# ioam3358 register map
Registers are 32-bit, access not given, no defined reset value unless marked. A register's access mark holds for its fields unless they carry their own. Addresses are absolute; registers are grouped by the start of their names; [hi:lo] are bit positions; {n}, {i} and the like mark numbered series; 'fields as' and 'values as' point back to an identical list.

## LCDC
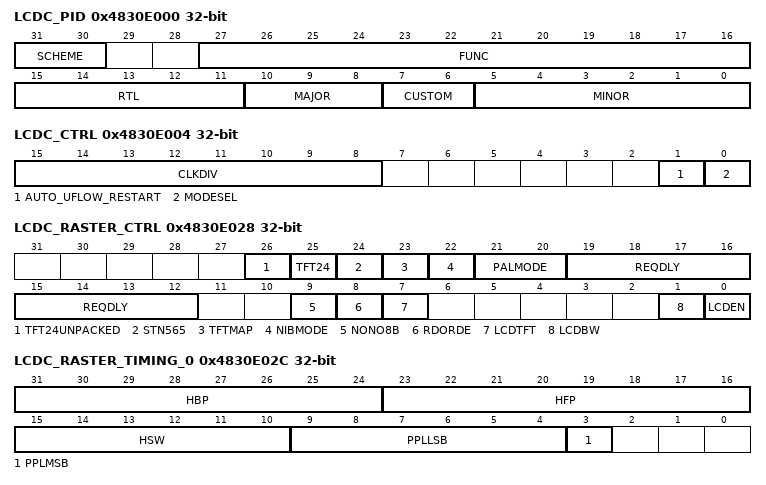
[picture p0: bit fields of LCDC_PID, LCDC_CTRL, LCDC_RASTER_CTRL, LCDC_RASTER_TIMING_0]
0x4830E000 LCDC_PID
  [31:30] SCHEME, [27:16] FUNC, [15:11] RTL, [10:8] MAJOR, [7:6] CUSTOM, [5:0] MINOR
0x4830E004 LCDC_CTRL
  [15:8] CLKDIV, [1] AUTO_UFLOW_RESTART, [0] MODESEL
0x4830E028 LCDC_RASTER_CTRL
  [26] TFT24UNPACKED, [25] TFT24, [24] STN565, [23] TFTMAP, [22] NIBMODE, [21:20] PALMODE, [19:12] REQDLY, [9] NONO8B, [8] RDORDE, [7] LCDTFT, [1] LCDBW, [0] LCDEN
0x4830E02C LCDC_RASTER_TIMING_0
  [31:24] HBP, [23:16] HFP, [15:10] HSW, [9:4] PPLLSB, [3] PPLMSB
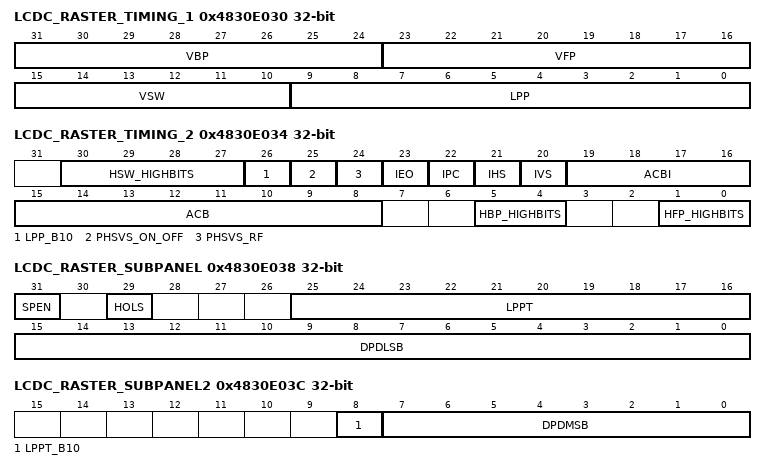
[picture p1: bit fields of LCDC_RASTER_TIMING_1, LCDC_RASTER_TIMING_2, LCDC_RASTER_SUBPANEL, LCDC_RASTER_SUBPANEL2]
0x4830E030 LCDC_RASTER_TIMING_1
  [31:24] VBP, [23:16] VFP, [15:10] VSW, [9:0] LPP
0x4830E034 LCDC_RASTER_TIMING_2
  [30:27] HSW_HIGHBITS, [26] LPP_B10, [25] PHSVS_ON_OFF, [24] PHSVS_RF, [23] IEO, [22] IPC, [21] IHS, [20] IVS, [19:16] ACBI, [15:8] ACB, [5:4] HBP_HIGHBITS, [1:0] HFP_HIGHBITS
0x4830E038 LCDC_RASTER_SUBPANEL
  [31] SPEN, [29] HOLS, [25:16] LPPT, [15:0] DPDLSB
0x4830E03C LCDC_RASTER_SUBPANEL2
  [8] LPPT_B10, [7:0] DPDMSB
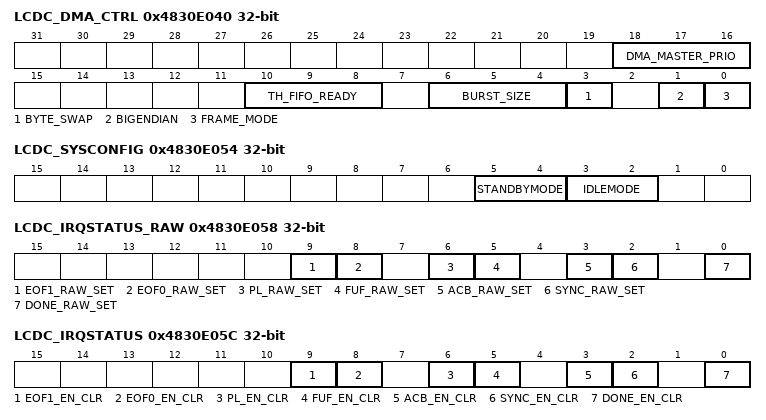
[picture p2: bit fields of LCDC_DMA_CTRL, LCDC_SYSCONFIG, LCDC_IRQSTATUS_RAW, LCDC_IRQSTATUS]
0x4830E040 LCDC_DMA_CTRL
  [18:16] DMA_MASTER_PRIO, [10:8] TH_FIFO_READY, [6:4] BURST_SIZE, [3] BYTE_SWAP, [1] BIGENDIAN, [0] FRAME_MODE
0x4830E044 LCDC_DMA_FB0_BASE
0x4830E048 LCDC_DMA_FB0_CEILING
0x4830E04C LCDC_DMA_FB1_BASE
0x4830E050 LCDC_DMA_FB1_CEILING
0x4830E054 LCDC_SYSCONFIG
  [5:4] STANDBYMODE, [3:2] IDLEMODE
0x4830E058 LCDC_IRQSTATUS_RAW
  [9] EOF1_RAW_SET, [8] EOF0_RAW_SET, [6] PL_RAW_SET, [5] FUF_RAW_SET, [3] ACB_RAW_SET, [2] SYNC_RAW_SET, [0] DONE_RAW_SET
0x4830E05C LCDC_IRQSTATUS
  [9] EOF1_EN_CLR, [8] EOF0_EN_CLR, [6] PL_EN_CLR, [5] FUF_EN_CLR, [3] ACB_EN_CLR, [2] SYNC_EN_CLR, [0] DONE_EN_CLR
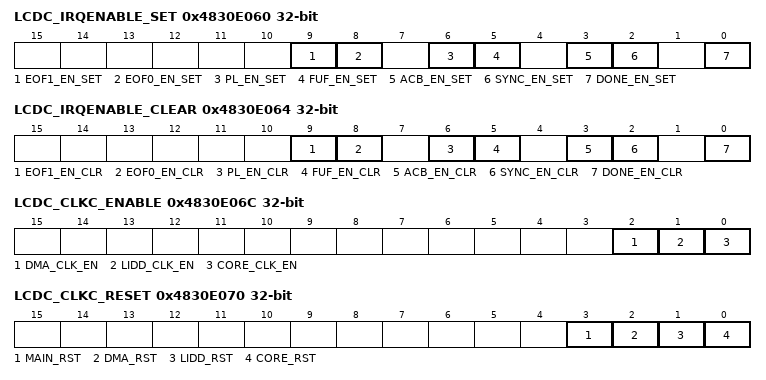
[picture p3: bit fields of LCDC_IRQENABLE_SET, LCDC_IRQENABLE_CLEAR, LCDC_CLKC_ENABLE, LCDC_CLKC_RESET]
0x4830E060 LCDC_IRQENABLE_SET
  [9] EOF1_EN_SET, [8] EOF0_EN_SET, [6] PL_EN_SET, [5] FUF_EN_SET, [3] ACB_EN_SET, [2] SYNC_EN_SET, [0] DONE_EN_SET
0x4830E064 LCDC_IRQENABLE_CLEAR
  fields as LCDC_IRQSTATUS
0x4830E068 LCDC_IRQEOI_VECTOR
0x4830E06C LCDC_CLKC_ENABLE
  [2] DMA_CLK_EN, [1] LIDD_CLK_EN, [0] CORE_CLK_EN
0x4830E070 LCDC_CLKC_RESET
  [3] MAIN_RST, [2] DMA_RST, [1] LIDD_RST, [0] CORE_RST

## LIDD
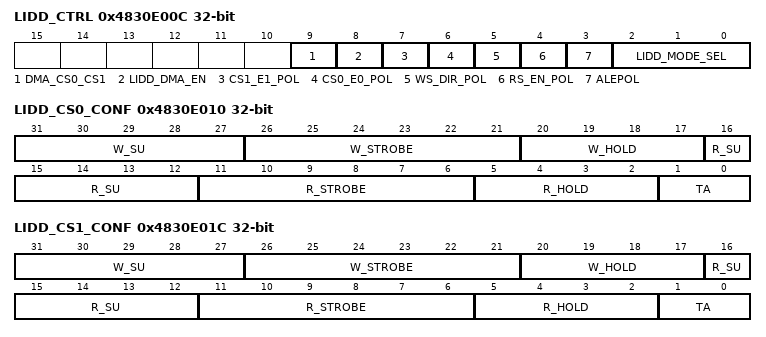
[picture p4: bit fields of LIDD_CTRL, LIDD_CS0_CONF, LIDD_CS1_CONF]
0x4830E00C LIDD_CTRL
  [9] DMA_CS0_CS1, [8] LIDD_DMA_EN, [7] CS1_E1_POL, [6] CS0_E0_POL, [5] WS_DIR_POL, [4] RS_EN_POL, [3] ALEPOL, [2:0] LIDD_MODE_SEL
0x4830E010 LIDD_CS0_CONF
  [31:27] W_SU, [26:21] W_STROBE, [20:17] W_HOLD, [16:12] R_SU, [11:6] R_STROBE, [5:2] R_HOLD, [1:0] TA
0x4830E014 LIDD_CS0_ADDR
  [15:0] ADR_INDX
0x4830E018 LIDD_CS0_DATA
  [15:0] DATA
0x4830E01C LIDD_CS1_CONF
  fields as LIDD_CS0_CONF
0x4830E020 LIDD_CS1_ADDR
  [15:0] ADR_INDX
0x4830E024 LIDD_CS1_DATA
  [15:0] DATA

## MDIO
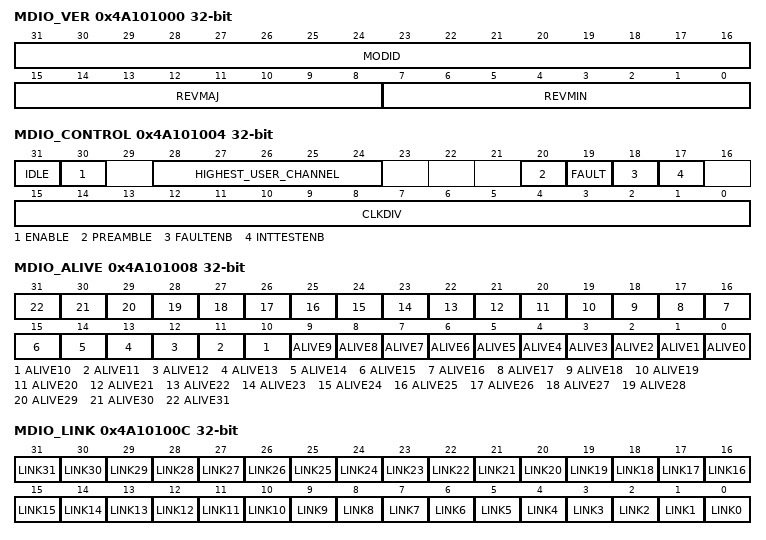
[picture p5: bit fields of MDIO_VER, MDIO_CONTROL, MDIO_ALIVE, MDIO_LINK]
0x4A101000 MDIO_VER
  [31:16] MODID, [15:8] REVMAJ, [7:0] REVMIN
0x4A101004 MDIO_CONTROL
  [31] IDLE, [30] ENABLE, [28:24] HIGHEST_USER_CHANNEL, [20] PREAMBLE, [19] FAULT, [18] FAULTENB, [17] INTTESTENB, [15:0] CLKDIV
0x4A101008 MDIO_ALIVE
  [n] ALIVE{n} (n=0..31)
0x4A10100C MDIO_LINK
  [n] LINK{n} (n=0..31)
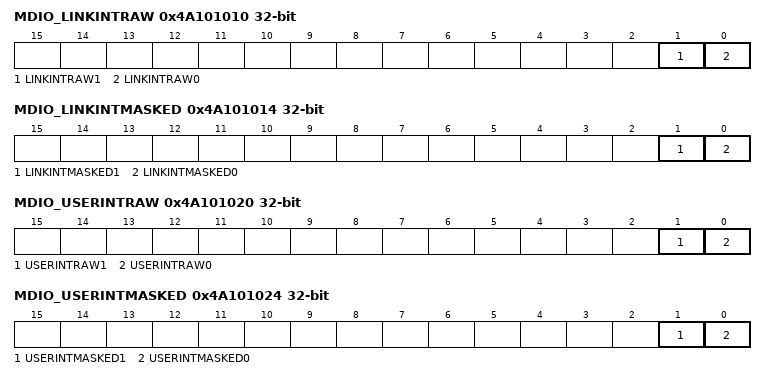
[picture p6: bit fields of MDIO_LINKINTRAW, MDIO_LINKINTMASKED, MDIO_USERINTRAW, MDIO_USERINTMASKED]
0x4A101010 MDIO_LINKINTRAW
  [1] LINKINTRAW1, [0] LINKINTRAW0
0x4A101014 MDIO_LINKINTMASKED
  [1] LINKINTMASKED1, [0] LINKINTMASKED0
0x4A101020 MDIO_USERINTRAW
  [1] USERINTRAW1, [0] USERINTRAW0
0x4A101024 MDIO_USERINTMASKED
  [1] USERINTMASKED1, [0] USERINTMASKED0
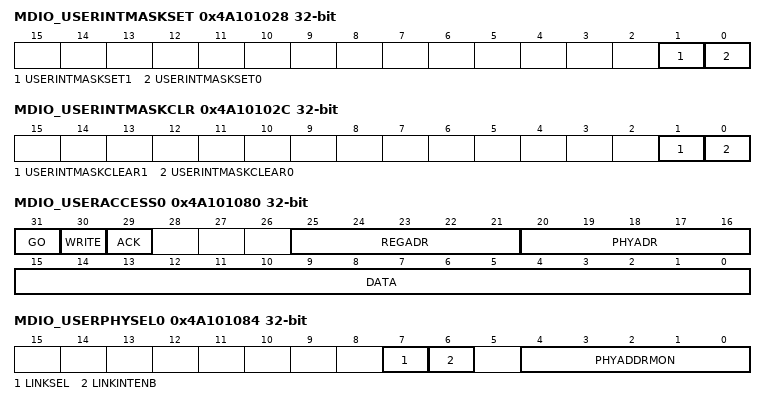
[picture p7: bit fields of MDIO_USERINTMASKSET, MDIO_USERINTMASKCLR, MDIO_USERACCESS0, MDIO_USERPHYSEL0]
0x4A101028 MDIO_USERINTMASKSET
  [1] USERINTMASKSET1, [0] USERINTMASKSET0
0x4A10102C MDIO_USERINTMASKCLR
  [1] USERINTMASKCLEAR1, [0] USERINTMASKCLEAR0
0x4A101080 MDIO_USERACCESS0
  [31] GO, [30] WRITE, [29] ACK, [25:21] REGADR, [20:16] PHYADR, [15:0] DATA
0x4A101084 MDIO_USERPHYSEL0
  [7] LINKSEL, [6] LINKINTENB, [4:0] PHYADDRMON
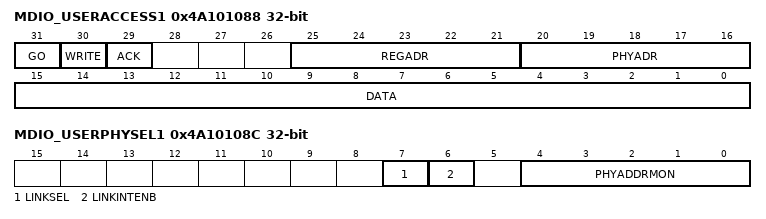
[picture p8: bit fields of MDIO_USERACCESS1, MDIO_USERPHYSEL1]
0x4A101088 MDIO_USERACCESS1
  fields as MDIO_USERACCESS0
0x4A10108C MDIO_USERPHYSEL1
  [7] LINKSEL, [6] LINKINTENB, [4:0] PHYADDRMON

## EPWM0
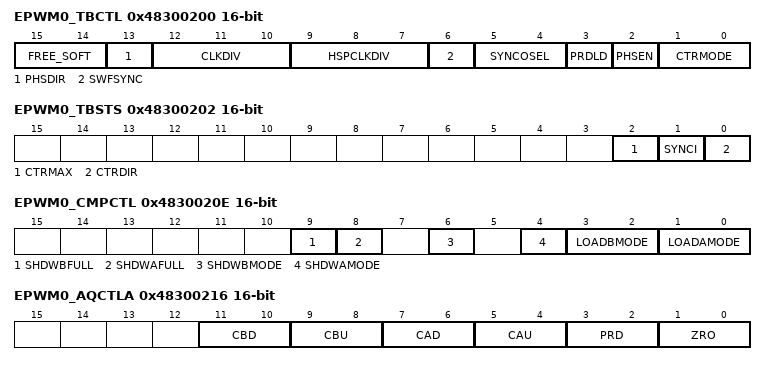
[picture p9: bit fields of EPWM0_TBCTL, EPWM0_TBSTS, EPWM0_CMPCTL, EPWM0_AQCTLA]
0x48300200 EPWM0_TBCTL 16-bit
  [15:14] FREE_SOFT, [13] PHSDIR, [12:10] CLKDIV, [9:7] HSPCLKDIV, [6] SWFSYNC, [5:4] SYNCOSEL, [3] PRDLD, [2] PHSEN, [1:0] CTRMODE
0x48300202 EPWM0_TBSTS 16-bit
  [2] CTRMAX, [1] SYNCI, [0] CTRDIR
0x48300204 EPWM0_TBPHSHR 16-bit
  [15:8] TBPHSH
0x48300206 EPWM0_TBPHS 16-bit
0x48300208 EPWM0_TBCNT 16-bit
0x4830020A EPWM0_TBPRD 16-bit
0x4830020E EPWM0_CMPCTL 16-bit
  [9] SHDWBFULL, [8] SHDWAFULL, [6] SHDWBMODE, [4] SHDWAMODE, [3:2] LOADBMODE, [1:0] LOADAMODE
0x48300210 EPWM0_CMPAHR 16-bit
  [15:8] CMPAHR
0x48300212 EPWM0_CMPA 16-bit
0x48300214 EPWM0_CMPB 16-bit
0x48300216 EPWM0_AQCTLA 16-bit
  [11:10] CBD, [9:8] CBU, [7:6] CAD, [5:4] CAU, [3:2] PRD, [1:0] ZRO
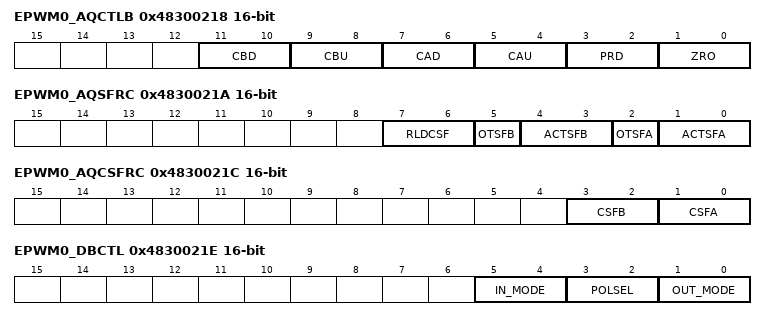
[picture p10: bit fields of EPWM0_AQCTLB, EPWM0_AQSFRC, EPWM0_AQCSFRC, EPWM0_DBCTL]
0x48300218 EPWM0_AQCTLB 16-bit
  [11:10] CBD, [9:8] CBU, [7:6] CAD, [5:4] CAU, [3:2] PRD, [1:0] ZRO
0x4830021A EPWM0_AQSFRC 16-bit
  [7:6] RLDCSF, [5] OTSFB, [4:3] ACTSFB, [2] OTSFA, [1:0] ACTSFA
0x4830021C EPWM0_AQCSFRC 16-bit
  [3:2] CSFB, [1:0] CSFA
0x4830021E EPWM0_DBCTL 16-bit
  [5:4] IN_MODE, [3:2] POLSEL, [1:0] OUT_MODE
0x48300220 EPWM0_DBRED 16-bit
  [9:0] DEL
0x48300222 EPWM0_DBFED 16-bit
  [9:0] DEL
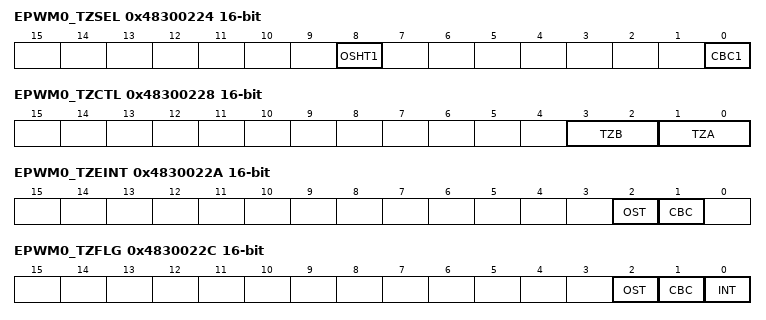
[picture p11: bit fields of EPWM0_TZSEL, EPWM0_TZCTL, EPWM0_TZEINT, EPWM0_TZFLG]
0x48300224 EPWM0_TZSEL 16-bit
  [8] OSHT1, [0] CBC1
0x48300228 EPWM0_TZCTL 16-bit
  [3:2] TZB, [1:0] TZA
0x4830022A EPWM0_TZEINT 16-bit
  [2] OST, [1] CBC
0x4830022C EPWM0_TZFLG 16-bit
  [2] OST, [1] CBC, [0] INT
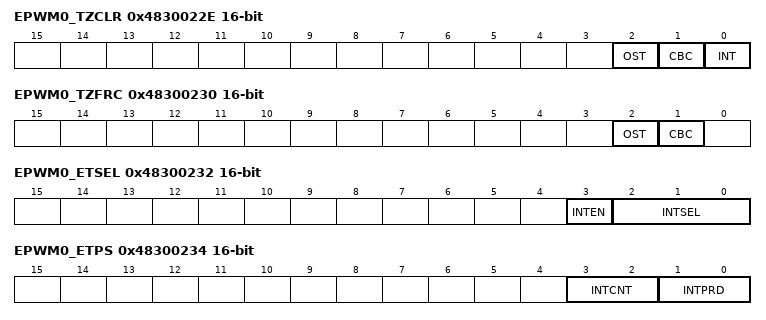
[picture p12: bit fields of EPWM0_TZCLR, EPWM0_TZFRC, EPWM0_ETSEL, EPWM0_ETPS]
0x4830022E EPWM0_TZCLR 16-bit
  [2] OST, [1] CBC, [0] INT
0x48300230 EPWM0_TZFRC 16-bit
  [2] OST, [1] CBC
0x48300232 EPWM0_ETSEL 16-bit
  [3] INTEN, [2:0] INTSEL
0x48300234 EPWM0_ETPS 16-bit
  [3:2] INTCNT, [1:0] INTPRD
0x48300236 EPWM0_ETFLG 16-bit
  [0] INT
0x48300238 EPWM0_ETCLR 16-bit
  [0] INT
0x4830023A EPWM0_ETFRC 16-bit
  [0] INT
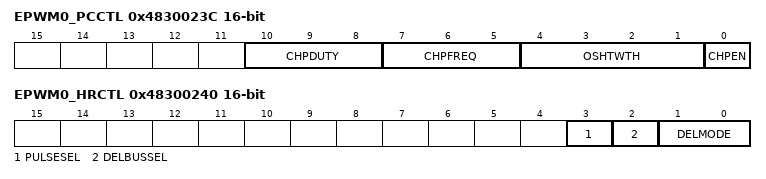
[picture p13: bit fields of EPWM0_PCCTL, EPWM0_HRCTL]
0x4830023C EPWM0_PCCTL 16-bit
  [10:8] CHPDUTY, [7:5] CHPFREQ, [4:1] OSHTWTH, [0] CHPEN
0x48300240 EPWM0_HRCTL 16-bit
  [3] PULSESEL, [2] DELBUSSEL, [1:0] DELMODE
